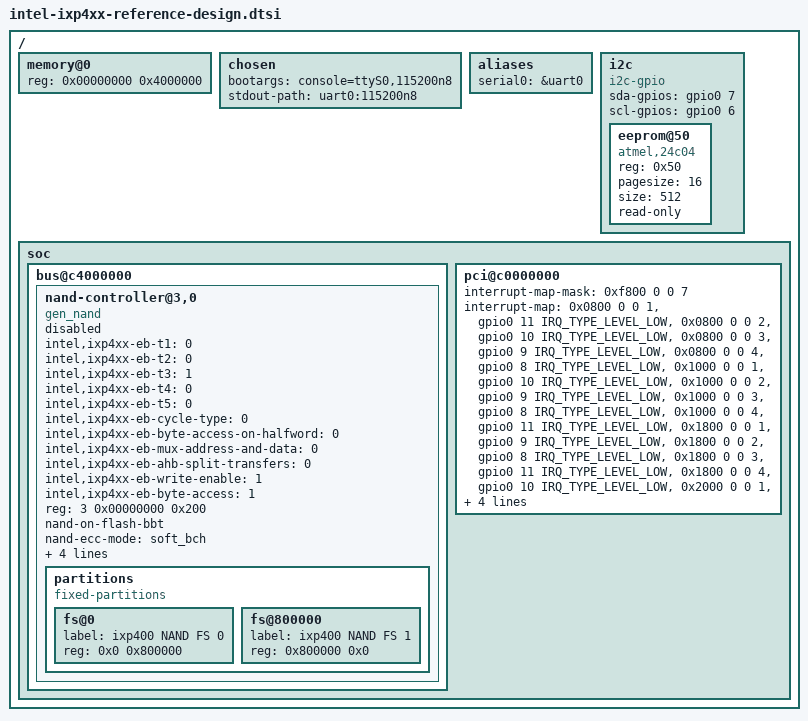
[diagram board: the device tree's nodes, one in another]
/ {
	memory@0 {
		device_type = "memory";
		reg = <0x00000000 0x4000000>;
	};
	chosen {
		bootargs = "console=ttyS0,115200n8";
		stdout-path = "uart0:115200n8";
	};
	aliases {
		serial0 = &uart0;
	};
	i2c {
		compatible = "i2c-gpio";
		sda-gpios = <&gpio0 7 (GPIO_ACTIVE_HIGH|GPIO_OPEN_DRAIN)>;
		scl-gpios = <&gpio0 6 (GPIO_ACTIVE_HIGH|GPIO_OPEN_DRAIN)>;
		#address-cells = <1>;
		#size-cells = <0>;
		eeprom@50 {
			compatible = "atmel,24c04";
			reg = <0x50>;
			pagesize = <16>;
			size = <512>;
			read-only;
		};
	};
	soc {
		bus@c4000000 {
			nand-controller@3,0 {
				status = "disabled";
				compatible = "gen_nand";
				intel,ixp4xx-eb-t1 = <0>;
				intel,ixp4xx-eb-t2 = <0>;
				intel,ixp4xx-eb-t3 = <1>;  
				intel,ixp4xx-eb-t4 = <0>;
				intel,ixp4xx-eb-t5 = <0>;
				intel,ixp4xx-eb-cycle-type = <0>;  
				intel,ixp4xx-eb-byte-access-on-halfword = <0>;
				intel,ixp4xx-eb-mux-address-and-data = <0>;
				intel,ixp4xx-eb-ahb-split-transfers = <0>;
				intel,ixp4xx-eb-write-enable = <1>;
				intel,ixp4xx-eb-byte-access = <1>;
				reg = <3 0x00000000 0x200>;
				nand-on-flash-bbt;
				nand-ecc-mode = "soft_bch";
				nand-ecc-step-size = <512>;
				nand-ecc-strength = <4>;
				nce-gpios = <&gpio0 12 GPIO_ACTIVE_HIGH>;  
				label = "ixp400 NAND";
				partitions {
					compatible = "fixed-partitions";
					#address-cells = <1>;
					#size-cells = <1>;
					fs@0 {
						label = "ixp400 NAND FS 0";
						reg = <0x0 0x800000>;
					};
					fs@800000 {
						label = "ixp400 NAND FS 1";
						reg = <0x800000 0x0>;
					};
				};
			};
		};
		pci@c0000000 {
			status = "okay";
			#interrupt-cells = <1>;
			interrupt-map-mask = <0xf800 0 0 7>;
			interrupt-map =
			<0x0800 0 0 1 &gpio0 11 IRQ_TYPE_LEVEL_LOW>,  
			<0x0800 0 0 2 &gpio0 10 IRQ_TYPE_LEVEL_LOW>,  
			<0x0800 0 0 3 &gpio0 9  IRQ_TYPE_LEVEL_LOW>,  
			<0x0800 0 0 4 &gpio0 8  IRQ_TYPE_LEVEL_LOW>,  
			<0x1000 0 0 1 &gpio0 10 IRQ_TYPE_LEVEL_LOW>,  
			<0x1000 0 0 2 &gpio0 9  IRQ_TYPE_LEVEL_LOW>,  
			<0x1000 0 0 3 &gpio0 8  IRQ_TYPE_LEVEL_LOW>,  
			<0x1000 0 0 4 &gpio0 11 IRQ_TYPE_LEVEL_LOW>,  
			<0x1800 0 0 1 &gpio0 9  IRQ_TYPE_LEVEL_LOW>,  
			<0x1800 0 0 2 &gpio0 8  IRQ_TYPE_LEVEL_LOW>,  
			<0x1800 0 0 3 &gpio0 11 IRQ_TYPE_LEVEL_LOW>,  
			<0x1800 0 0 4 &gpio0 10 IRQ_TYPE_LEVEL_LOW>,  
			<0x2000 0 0 1 &gpio0 8  IRQ_TYPE_LEVEL_LOW>,  
			<0x2000 0 0 2 &gpio0 11 IRQ_TYPE_LEVEL_LOW>,  
			<0x2000 0 0 3 &gpio0 10 IRQ_TYPE_LEVEL_LOW>,  
			<0x2000 0 0 4 &gpio0 9  IRQ_TYPE_LEVEL_LOW>;  
		};
	};
};
